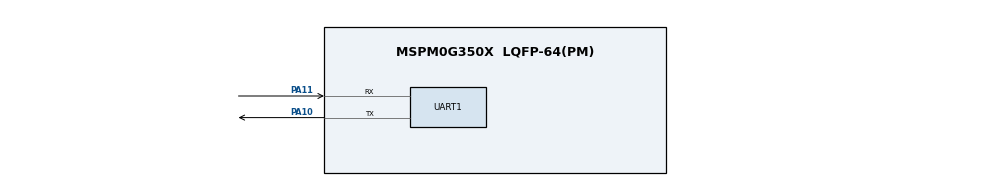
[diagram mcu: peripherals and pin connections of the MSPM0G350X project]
/**
 * @cliArgs --device "MSPM0G350X" --part "Default" --package "LQFP-64(PM)" --product "mspm0_sdk@2.10.00.04"
 * @versions {"tool":"1.26.2+4477"}
 */

/**
 * Import the modules used in this configuration.
 */
const GPIO   = scripting.addModule("/ti/driverlib/GPIO", {}, false);
const GPIO1  = GPIO.addInstance();
const SYSCTL = scripting.addModule("/ti/driverlib/SYSCTL");
const UART   = scripting.addModule("/ti/driverlib/UART", {}, false);
const UART1  = UART.addInstance();

/**
 * Write custom configuration values to the imported modules.
 */
const divider9       = system.clockTree["UDIV"];
divider9.divideValue = 2;

const gate7  = system.clockTree["MFCLKGATE"];
gate7.enable = true;

const multiplier2         = system.clockTree["PLL_QDIV"];
multiplier2.multiplyValue = 4;

const mux4       = system.clockTree["EXHFMUX"];
mux4.inputSelect = "EXHFMUX_XTAL";

const mux8       = system.clockTree["HSCLKMUX"];
mux8.inputSelect = "HSCLKMUX_SYSPLL0";

const mux12       = system.clockTree["SYSPLLMUX"];
mux12.inputSelect = "zSYSPLLMUX_HFCLK";

const pinFunction4        = system.clockTree["HFXT"];
pinFunction4.inputFreq    = 40;
pinFunction4.enable       = true;
pinFunction4.HFXTStartup  = 10;
pinFunction4.HFCLKMonitor = true;

GPIO1.$name                         = "LED";
GPIO1.port                          = "PORTB";
GPIO1.associatedPins[0].$name       = "PIN_22";
GPIO1.associatedPins[0].assignedPin = "22";

const Board = scripting.addModule("/ti/driverlib/Board", {}, false);

SYSCTL.forceDefaultClkConfig = true;
SYSCTL.clockTreeEn           = true;

UART1.$name                      = "UART_0";
UART1.targetBaudRate             = 115200;
UART1.enabledInterrupts          = ["DMA_DONE_TX"];
UART1.enabledDMATXTriggers       = "DL_UART_DMA_INTERRUPT_TX";
UART1.peripheral.rxPin.$assign   = "PA11";
UART1.peripheral.txPin.$assign   = "PA10";
UART1.txPinConfig.$name          = "ti_driverlib_gpio_GPIOPinGeneric0";
UART1.rxPinConfig.$name          = "ti_driverlib_gpio_GPIOPinGeneric1";
UART1.DMA_CHANNEL_TX.$name       = "DMA_UART0Tx";
UART1.DMA_CHANNEL_TX.addressMode = "b2f";
UART1.DMA_CHANNEL_TX.srcLength   = "BYTE";
UART1.DMA_CHANNEL_TX.dstLength   = "BYTE";

/**
 * Pinmux solution for unlocked pins/peripherals. This ensures that minor changes to the automatic solver in a future
 * version of the tool will not impact the pinmux you originally saw.  These lines can be completely deleted in order to
 * re-solve from scratch.
 */
pinFunction4.peripheral.$suggestSolution           = "SYSCTL";
pinFunction4.peripheral.hfxInPin.$suggestSolution  = "PA5";
pinFunction4.peripheral.hfxOutPin.$suggestSolution = "PA6";
GPIO1.associatedPins[0].pin.$suggestSolution       = "PB22";
Board.peripheral.$suggestSolution                  = "DEBUGSS";
Board.peripheral.swclkPin.$suggestSolution         = "PA20";
Board.peripheral.swdioPin.$suggestSolution         = "PA19";
UART1.peripheral.$suggestSolution                  = "UART0";
UART1.DMA_CHANNEL_TX.peripheral.$suggestSolution   = "DMA_CH0";
